# ioat91sam7x256 register map
Registers are 32-bit, access not given, no defined reset value unless marked. A register's access mark holds for its fields unless they carry their own. Addresses are absolute; registers are grouped by the start of their names; [hi:lo] are bit positions; {n}, {i} and the like mark numbered series; 'fields as' and 'values as' point back to an identical list.

## RSTC
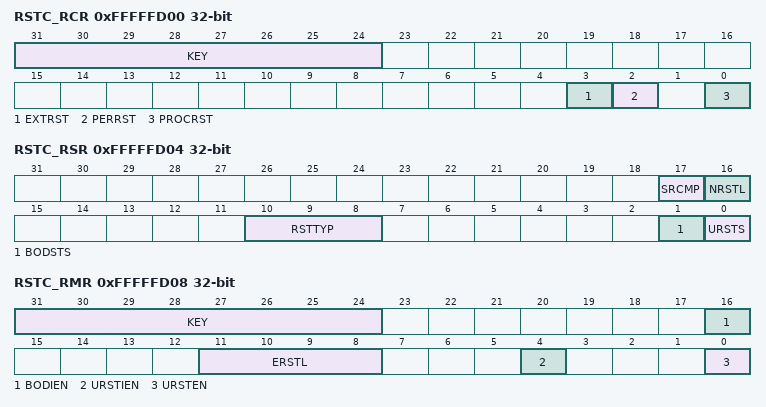
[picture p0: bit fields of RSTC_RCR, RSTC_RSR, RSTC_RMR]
0xFFFFFD00 RSTC_RCR
  [31:24] KEY, [3] EXTRST, [2] PERRST, [0] PROCRST
0xFFFFFD04 RSTC_RSR
  [17] SRCMP, [16] NRSTL, [10:8] RSTTYP, [1] BODSTS, [0] URSTS
0xFFFFFD08 RSTC_RMR
  [31:24] KEY, [16] BODIEN, [11:8] ERSTL, [4] URSTIEN, [0] URSTEN

## RTTC
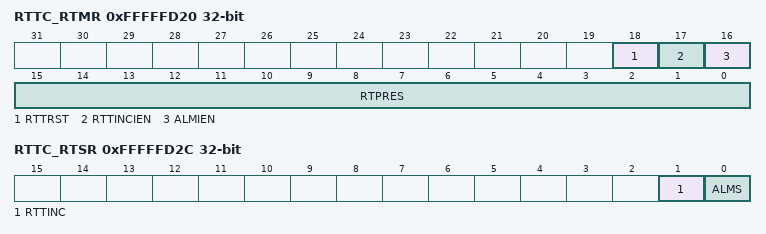
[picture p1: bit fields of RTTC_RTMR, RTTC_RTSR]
0xFFFFFD20 RTTC_RTMR
  [18] RTTRST, [17] RTTINCIEN, [16] ALMIEN, [15:0] RTPRES
0xFFFFFD24 RTTC_RTAR
  [31:0] ALMV
0xFFFFFD28 RTTC_RTVR
  [31:0] CRTV
0xFFFFFD2C RTTC_RTSR
  [1] RTTINC, [0] ALMS

## PITC
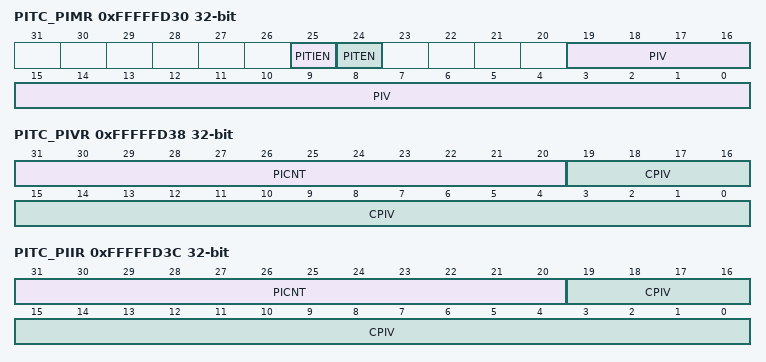
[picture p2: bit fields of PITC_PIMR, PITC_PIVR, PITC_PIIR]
0xFFFFFD30 PITC_PIMR
  [25] PITIEN, [24] PITEN, [19:0] PIV
0xFFFFFD34 PITC_PISR
  [0] PITS
0xFFFFFD38 PITC_PIVR
  [31:20] PICNT, [19:0] CPIV
0xFFFFFD3C PITC_PIIR
  [31:20] PICNT, [19:0] CPIV

## WDTC
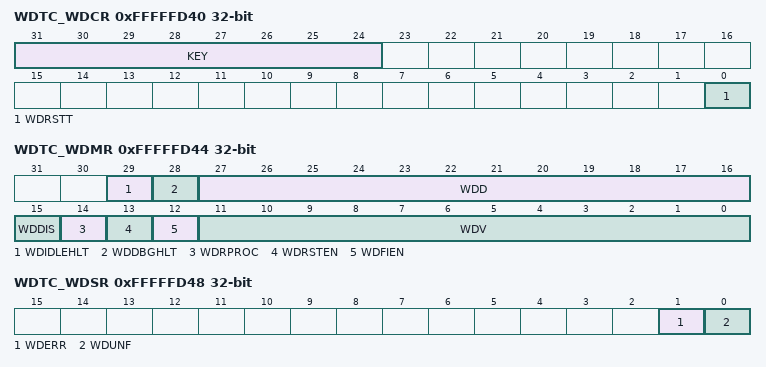
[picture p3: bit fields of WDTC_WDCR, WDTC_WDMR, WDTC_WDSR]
0xFFFFFD40 WDTC_WDCR
  [31:24] KEY, [0] WDRSTT
0xFFFFFD44 WDTC_WDMR
  [29] WDIDLEHLT, [28] WDDBGHLT, [27:16] WDD, [15] WDDIS, [14] WDRPROC, [13] WDRSTEN, [12] WDFIEN, [11:0] WDV
0xFFFFFD48 WDTC_WDSR
  [1] WDERR, [0] WDUNF

## MC
0xFFFFFF00 MC_RCR
  [0] RCB
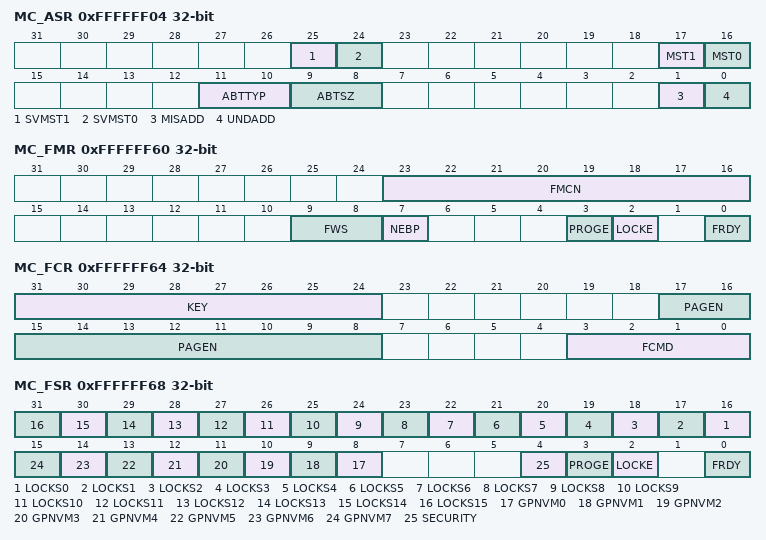
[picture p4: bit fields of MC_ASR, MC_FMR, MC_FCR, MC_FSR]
0xFFFFFF04 MC_ASR
  [25] SVMST1, [24] SVMST0, [17] MST1, [16] MST0, [11:10] ABTTYP, [9:8] ABTSZ, [1] MISADD, [0] UNDADD
0xFFFFFF08 MC_AASR
0xFFFFFF60 MC_FMR
  [23:16] FMCN, [9:8] FWS, [7] NEBP, [3] PROGE, [2] LOCKE, [0] FRDY
0xFFFFFF64 MC_FCR
  [31:24] KEY, [17:8] PAGEN, [3:0] FCMD
0xFFFFFF68 MC_FSR
  [n+16] LOCKS{n} (n=0..15), [n+8] GPNVM{n} (n=0..7), [4] SECURITY, [3] PROGE, [2] LOCKE, [0] FRDY

## SPI1
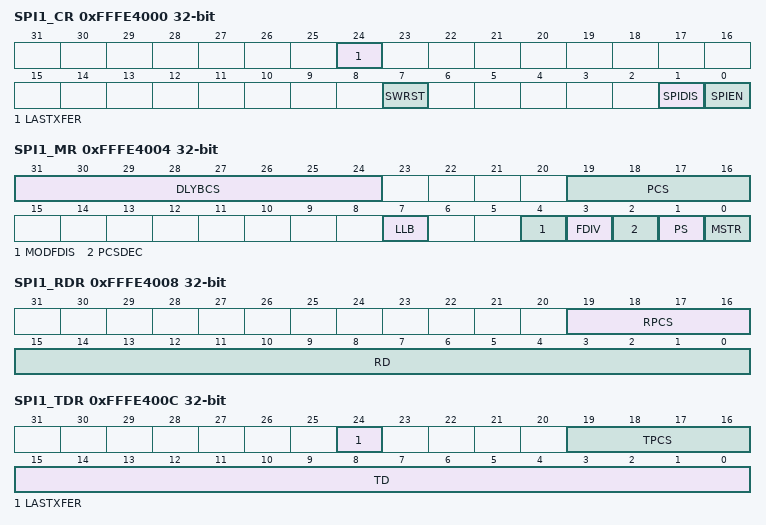
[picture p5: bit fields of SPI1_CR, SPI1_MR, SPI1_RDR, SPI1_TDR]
0xFFFE4000 SPI1_CR
  [24] LASTXFER, [7] SWRST, [1] SPIDIS, [0] SPIEN
0xFFFE4004 SPI1_MR
  [31:24] DLYBCS, [19:16] PCS, [7] LLB, [4] MODFDIS, [3] FDIV, [2] PCSDEC, [1] PS, [0] MSTR
0xFFFE4008 SPI1_RDR
  [19:16] RPCS, [15:0] RD
0xFFFE400C SPI1_TDR
  [24] LASTXFER, [19:16] TPCS, [15:0] TD
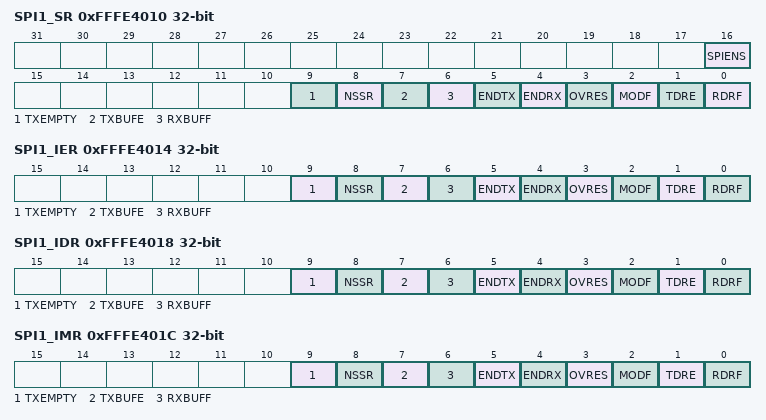
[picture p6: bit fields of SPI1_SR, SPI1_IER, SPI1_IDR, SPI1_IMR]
0xFFFE4010 SPI1_SR
  [16] SPIENS, [9] TXEMPTY, [8] NSSR, [7] TXBUFE, [6] RXBUFF, [5] ENDTX, [4] ENDRX, [3] OVRES, [2] MODF, [1] TDRE, [0] RDRF
0xFFFE4014 SPI1_IER
  [9] TXEMPTY, [8] NSSR, [7] TXBUFE, [6] RXBUFF, [5] ENDTX, [4] ENDRX, [3] OVRES, [2] MODF, [1] TDRE, [0] RDRF
0xFFFE4018 SPI1_IDR
  fields as SPI1_IER
0xFFFE401C SPI1_IMR
  fields as SPI1_IER
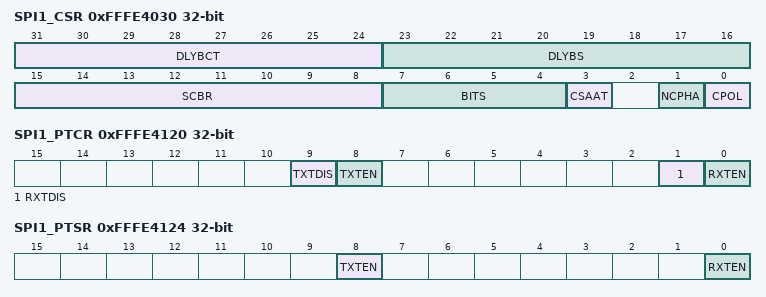
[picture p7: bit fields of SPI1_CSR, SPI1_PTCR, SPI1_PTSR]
0xFFFE4030 SPI1_CSR
  [31:24] DLYBCT, [23:16] DLYBS, [15:8] SCBR, [7:4] BITS, [3] CSAAT, [1] NCPHA, [0] CPOL
0xFFFE4100 SPI1_RPR
0xFFFE4104 SPI1_RCR
0xFFFE4108 SPI1_TPR
0xFFFE410C SPI1_TCR
0xFFFE4110 SPI1_RNPR
0xFFFE4114 SPI1_RNCR
0xFFFE4118 SPI1_TNPR
0xFFFE411C SPI1_TNCR
0xFFFE4120 SPI1_PTCR
  [9] TXTDIS, [8] TXTEN, [1] RXTDIS, [0] RXTEN
0xFFFE4124 SPI1_PTSR
  [8] TXTEN, [0] RXTEN

## SPI0
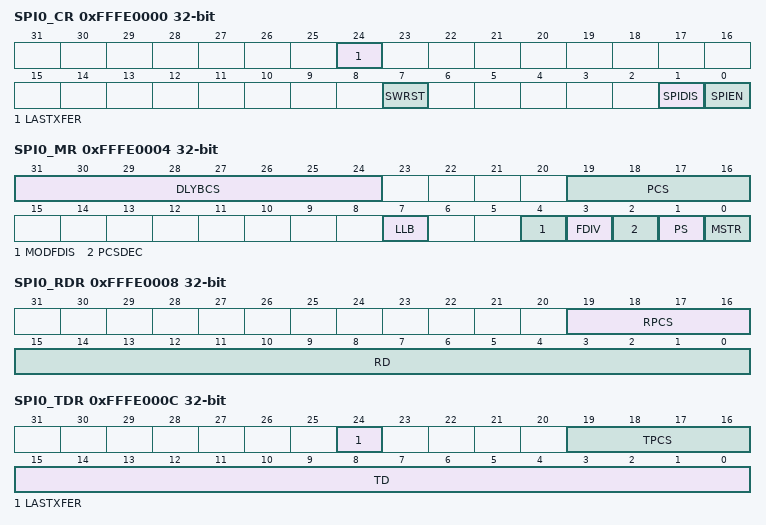
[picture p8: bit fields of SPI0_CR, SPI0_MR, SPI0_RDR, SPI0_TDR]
0xFFFE0000 SPI0_CR
  [24] LASTXFER, [7] SWRST, [1] SPIDIS, [0] SPIEN
0xFFFE0004 SPI0_MR
  [31:24] DLYBCS, [19:16] PCS, [7] LLB, [4] MODFDIS, [3] FDIV, [2] PCSDEC, [1] PS, [0] MSTR
0xFFFE0008 SPI0_RDR
  [19:16] RPCS, [15:0] RD
0xFFFE000C SPI0_TDR
  [24] LASTXFER, [19:16] TPCS, [15:0] TD
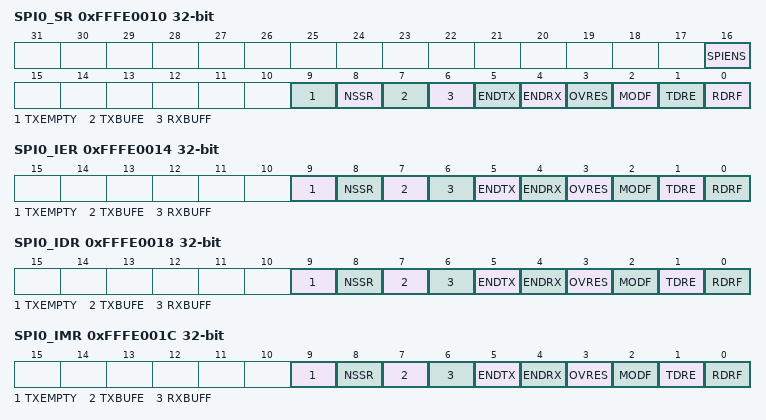
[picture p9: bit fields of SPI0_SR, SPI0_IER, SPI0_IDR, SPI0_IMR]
0xFFFE0010 SPI0_SR
  [16] SPIENS, [9] TXEMPTY, [8] NSSR, [7] TXBUFE, [6] RXBUFF, [5] ENDTX, [4] ENDRX, [3] OVRES, [2] MODF, [1] TDRE, [0] RDRF
0xFFFE0014 SPI0_IER
  [9] TXEMPTY, [8] NSSR, [7] TXBUFE, [6] RXBUFF, [5] ENDTX, [4] ENDRX, [3] OVRES, [2] MODF, [1] TDRE, [0] RDRF
0xFFFE0018 SPI0_IDR
  fields as SPI0_IER
0xFFFE001C SPI0_IMR
  fields as SPI0_IER
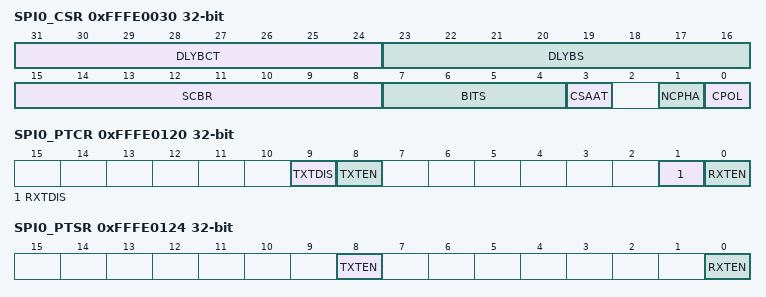
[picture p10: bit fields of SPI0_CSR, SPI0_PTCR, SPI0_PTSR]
0xFFFE0030 SPI0_CSR
  [31:24] DLYBCT, [23:16] DLYBS, [15:8] SCBR, [7:4] BITS, [3] CSAAT, [1] NCPHA, [0] CPOL
0xFFFE0100 SPI0_RPR
0xFFFE0104 SPI0_RCR
0xFFFE0108 SPI0_TPR
0xFFFE010C SPI0_TCR
0xFFFE0110 SPI0_RNPR
0xFFFE0114 SPI0_RNCR
0xFFFE0118 SPI0_TNPR
0xFFFE011C SPI0_TNCR
0xFFFE0120 SPI0_PTCR
  [9] TXTDIS, [8] TXTEN, [1] RXTDIS, [0] RXTEN
0xFFFE0124 SPI0_PTSR
  [8] TXTEN, [0] RXTEN

## US1
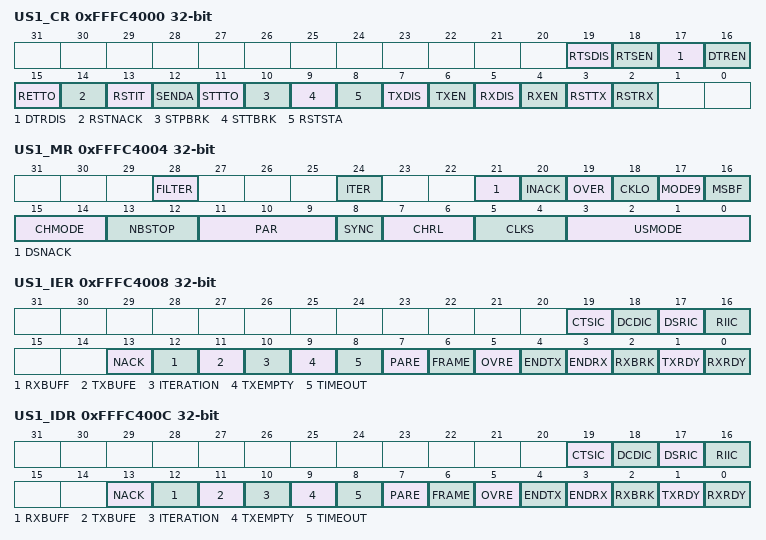
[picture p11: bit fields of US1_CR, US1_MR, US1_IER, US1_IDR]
0xFFFC4000 US1_CR
  [19] RTSDIS, [18] RTSEN, [17] DTRDIS, [16] DTREN, [15] RETTO, [14] RSTNACK, [13] RSTIT, [12] SENDA, [11] STTTO, [10] STPBRK, [9] STTBRK, [8] RSTSTA, [7] TXDIS, [6] TXEN, [5] RXDIS, [4] RXEN, [3] RSTTX, [2] RSTRX
0xFFFC4004 US1_MR
  [28] FILTER, [24] ITER, [21] DSNACK, [20] INACK, [19] OVER, [18] CKLO, [17] MODE9, [16] MSBF, [15:14] CHMODE, [13:12] NBSTOP, [11:9] PAR, [8] SYNC, [7:6] CHRL, [5:4] CLKS, [3:0] USMODE
0xFFFC4008 US1_IER
  [19] CTSIC, [18] DCDIC, [17] DSRIC, [16] RIIC, [13] NACK, [12] RXBUFF, [11] TXBUFE, [10] ITERATION, [9] TXEMPTY, [8] TIMEOUT, [7] PARE, [6] FRAME, [5] OVRE, [4] ENDTX, [3] ENDRX, [2] RXBRK, [1] TXRDY, [0] RXRDY
0xFFFC400C US1_IDR
  fields as US1_IER
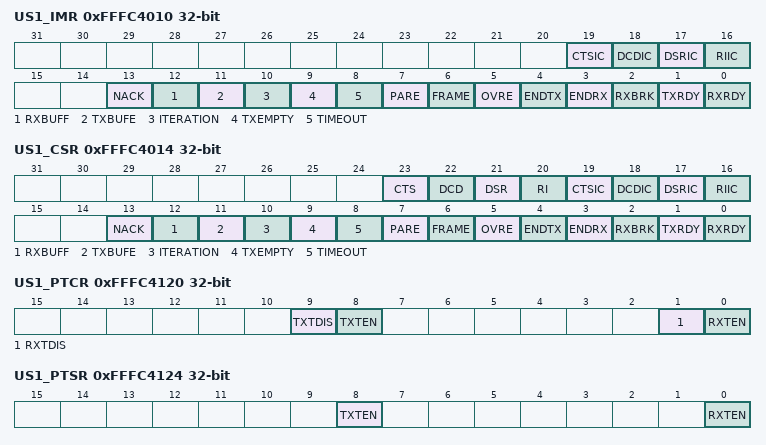
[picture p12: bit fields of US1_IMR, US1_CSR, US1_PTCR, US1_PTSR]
0xFFFC4010 US1_IMR
  fields as US1_IER
0xFFFC4014 US1_CSR
  [23] CTS, [22] DCD, [21] DSR, [20] RI, [19] CTSIC, [18] DCDIC, [17] DSRIC, [16] RIIC, [13] NACK, [12] RXBUFF, [11] TXBUFE, [10] ITERATION, [9] TXEMPTY, [8] TIMEOUT, [7] PARE, [6] FRAME, [5] OVRE, [4] ENDTX, [3] ENDRX, [2] RXBRK, [1] TXRDY, [0] RXRDY
0xFFFC4018 US1_RHR
0xFFFC401C US1_THR
0xFFFC4020 US1_BRGR
0xFFFC4024 US1_RTOR
0xFFFC4028 US1_TTGR
0xFFFC4040 US1_FIDI
0xFFFC4044 US1_NER
0xFFFC404C US1_IF
0xFFFC4100 US1_RPR
0xFFFC4104 US1_RCR
0xFFFC4108 US1_TPR
0xFFFC410C US1_TCR
0xFFFC4110 US1_RNPR
0xFFFC4114 US1_RNCR
0xFFFC4118 US1_TNPR
0xFFFC411C US1_TNCR
0xFFFC4120 US1_PTCR
  [9] TXTDIS, [8] TXTEN, [1] RXTDIS, [0] RXTEN
0xFFFC4124 US1_PTSR
  [8] TXTEN, [0] RXTEN
